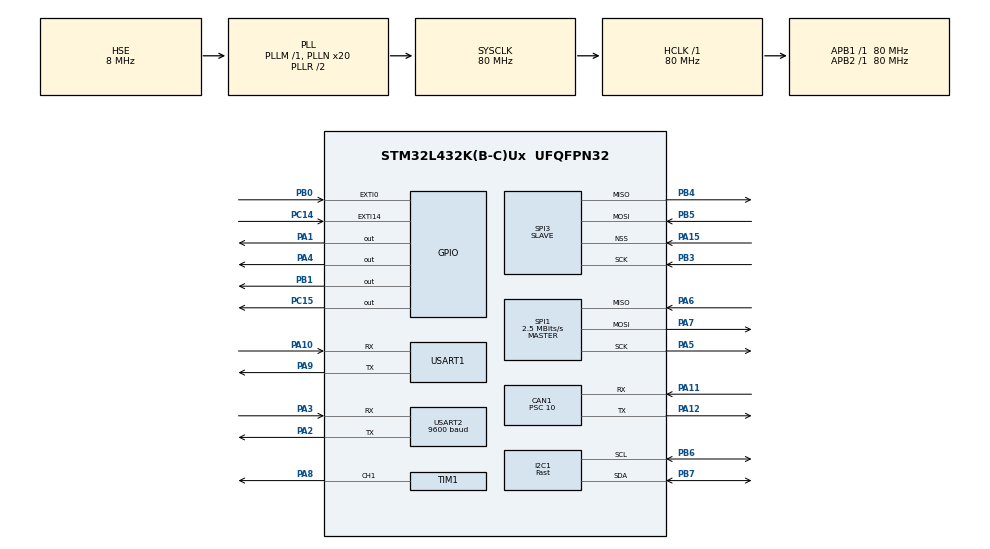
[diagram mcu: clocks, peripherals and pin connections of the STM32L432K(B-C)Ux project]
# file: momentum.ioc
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ADC1.Channel-0\#ChannelRegularConversion=ADC_CHANNEL_VREFINT
ADC1.Channel-1\#ChannelRegularConversion=ADC_CHANNEL_TEMPSENSOR
ADC1.NbrOfConversion=2
ADC1.NbrOfConversionFlag=1
ADC1.OffsetNumber-0\#ChannelRegularConversion=ADC_OFFSET_NONE
ADC1.OffsetNumber-1\#ChannelRegularConversion=ADC_OFFSET_NONE
ADC1.Overrun=ADC_OVR_DATA_OVERWRITTEN
ADC1.OversamplingMode=DISABLE
ADC1.Rank-0\#ChannelRegularConversion=1
ADC1.Rank-1\#ChannelRegularConversion=2
ADC1.SamplingTime-0\#ChannelRegularConversion=ADC_SAMPLETIME_640CYCLES_5
ADC1.SamplingTime-1\#ChannelRegularConversion=ADC_SAMPLETIME_640CYCLES_5
ADC1.master=1
CAN1.ABOM=ENABLE
CAN1.BS1=CAN_BS1_13TQ
CAN1.BS2=CAN_BS2_2TQ
CAN1.CalculateBaudRate=500000
CAN1.CalculateTimeBit=2000
CAN1.CalculateTimeQuantum=125.0
CAN1.NART=ENABLE
CAN1.Prescaler=10
Dma.ADC1.9.Direction=DMA_PERIPH_TO_MEMORY
Dma.ADC1.9.Instance=DMA1_Channel1
Dma.ADC1.9.MemDataAlignment=DMA_MDATAALIGN_WORD
Dma.ADC1.9.MemInc=DMA_MINC_ENABLE
Dma.ADC1.9.Mode=DMA_NORMAL
Dma.ADC1.9.PeriphDataAlignment=DMA_PDATAALIGN_WORD
Dma.ADC1.9.PeriphInc=DMA_PINC_DISABLE
Dma.ADC1.9.Priority=DMA_PRIORITY_LOW
Dma.Request0=SPI1_RX
Dma.Request1=SPI1_TX
Dma.Request2=USART2_RX
Dma.Request3=USART2_TX
Dma.Request4=SPI3_TX
Dma.Request5=SPI3_RX
Dma.Request6=TIM1_CH1
Dma.Request7=USART1_RX
Dma.Request8=USART1_TX
Dma.Request9=ADC1
Dma.SPI1_RX.0.Direction=DMA_PERIPH_TO_MEMORY
Dma.SPI1_RX.0.Instance=DMA2_Channel3
Dma.SPI1_RX.0.MemDataAlignment=DMA_MDATAALIGN_BYTE
Dma.SPI1_RX.0.MemInc=DMA_MINC_ENABLE
Dma.SPI1_RX.0.Mode=DMA_NORMAL
Dma.SPI1_RX.0.PeriphDataAlignment=DMA_PDATAALIGN_BYTE
Dma.SPI1_RX.0.PeriphInc=DMA_PINC_DISABLE
Dma.SPI1_RX.0.Priority=DMA_PRIORITY_LOW
Dma.SPI1_TX.1.Direction=DMA_MEMORY_TO_PERIPH
Dma.SPI1_TX.1.Instance=DMA1_Channel3
Dma.SPI1_TX.1.MemDataAlignment=DMA_MDATAALIGN_BYTE
Dma.SPI1_TX.1.MemInc=DMA_MINC_ENABLE
Dma.SPI1_TX.1.Mode=DMA_NORMAL
Dma.SPI1_TX.1.PeriphDataAlignment=DMA_PDATAALIGN_BYTE
Dma.SPI1_TX.1.PeriphInc=DMA_PINC_DISABLE
Dma.SPI1_TX.1.Priority=DMA_PRIORITY_LOW
Dma.SPI3_RX.5.Direction=DMA_PERIPH_TO_MEMORY
Dma.SPI3_RX.5.Instance=DMA2_Channel1
Dma.SPI3_RX.5.MemDataAlignment=DMA_MDATAALIGN_BYTE
Dma.SPI3_RX.5.MemInc=DMA_MINC_ENABLE
Dma.SPI3_RX.5.Mode=DMA_NORMAL
Dma.SPI3_RX.5.PeriphDataAlignment=DMA_PDATAALIGN_BYTE
Dma.SPI3_RX.5.PeriphInc=DMA_PINC_DISABLE
Dma.SPI3_RX.5.Priority=DMA_PRIORITY_LOW
Dma.SPI3_TX.4.Direction=DMA_MEMORY_TO_PERIPH
Dma.SPI3_TX.4.Instance=DMA2_Channel2
Dma.SPI3_TX.4.MemDataAlignment=DMA_MDATAALIGN_BYTE
Dma.SPI3_TX.4.MemInc=DMA_MINC_ENABLE
Dma.SPI3_TX.4.Mode=DMA_NORMAL
Dma.SPI3_TX.4.PeriphDataAlignment=DMA_PDATAALIGN_BYTE
Dma.SPI3_TX.4.PeriphInc=DMA_PINC_DISABLE
Dma.SPI3_TX.4.Priority=DMA_PRIORITY_LOW
Dma.TIM1_CH1.6.Direction=DMA_MEMORY_TO_PERIPH
Dma.TIM1_CH1.6.Instance=DMA1_Channel2
Dma.TIM1_CH1.6.MemDataAlignment=DMA_MDATAALIGN_HALFWORD
Dma.TIM1_CH1.6.MemInc=DMA_MINC_ENABLE
Dma.TIM1_CH1.6.Mode=DMA_NORMAL
Dma.TIM1_CH1.6.PeriphDataAlignment=DMA_PDATAALIGN_HALFWORD
Dma.TIM1_CH1.6.PeriphInc=DMA_PINC_DISABLE
Dma.TIM1_CH1.6.Priority=DMA_PRIORITY_LOW
Dma.USART1_RX.7.Direction=DMA_PERIPH_TO_MEMORY
Dma.USART1_RX.7.Instance=DMA1_Channel5
Dma.USART1_RX.7.MemDataAlignment=DMA_MDATAALIGN_BYTE
Dma.USART1_RX.7.MemInc=DMA_MINC_ENABLE
Dma.USART1_RX.7.Mode=DMA_NORMAL
Dma.USART1_RX.7.PeriphDataAlignment=DMA_PDATAALIGN_BYTE
Dma.USART1_RX.7.PeriphInc=DMA_PINC_DISABLE
Dma.USART1_RX.7.Priority=DMA_PRIORITY_LOW
Dma.USART1_TX.8.Direction=DMA_MEMORY_TO_PERIPH
Dma.USART1_TX.8.Instance=DMA1_Channel4
Dma.USART1_TX.8.MemDataAlignment=DMA_MDATAALIGN_BYTE
Dma.USART1_TX.8.MemInc=DMA_MINC_ENABLE
Dma.USART1_TX.8.Mode=DMA_NORMAL
Dma.USART1_TX.8.PeriphDataAlignment=DMA_PDATAALIGN_BYTE
Dma.USART1_TX.8.PeriphInc=DMA_PINC_DISABLE
Dma.USART1_TX.8.Priority=DMA_PRIORITY_LOW
Dma.USART2_RX.2.Direction=DMA_PERIPH_TO_MEMORY
Dma.USART2_RX.2.Instance=DMA1_Channel6
Dma.USART2_RX.2.MemDataAlignment=DMA_MDATAALIGN_BYTE
Dma.USART2_RX.2.MemInc=DMA_MINC_ENABLE
Dma.USART2_RX.2.Mode=DMA_CIRCULAR
Dma.USART2_RX.2.PeriphDataAlignment=DMA_PDATAALIGN_BYTE
Dma.USART2_RX.2.PeriphInc=DMA_PINC_DISABLE
Dma.USART2_RX.2.Priority=DMA_PRIORITY_LOW
Dma.USART2_TX.3.Direction=DMA_MEMORY_TO_PERIPH
Dma.USART2_TX.3.Instance=DMA1_Channel7
Dma.USART2_TX.3.MemDataAlignment=DMA_MDATAALIGN_BYTE
Dma.USART2_TX.3.MemInc=DMA_MINC_ENABLE
Dma.USART2_TX.3.Mode=DMA_NORMAL
Dma.USART2_TX.3.PeriphDataAlignment=DMA_PDATAALIGN_BYTE
Dma.USART2_TX.3.PeriphInc=DMA_PINC_DISABLE
Dma.USART2_TX.3.Priority=DMA_PRIORITY_LOW
I2C1.I2C_Speed_Mode=I2C_Fast
I2C1.Timing=0x00F12981
Mcu.Family=STM32L4
Mcu.Name=STM32L432K(B-C)Ux
Mcu.Package=UFQFPN32
NVIC.CAN1_RX0_IRQn=true\:1\:0\:true\:false\:true\:true\:true\:true
NVIC.CAN1_RX1_IRQn=true\:1\:0\:true\:false\:true\:true\:true\:true
NVIC.DMA1_Channel1_IRQn=true\:3\:0\:true\:false\:true\:false\:true\:true
NVIC.DMA1_Channel2_IRQn=true\:3\:0\:true\:false\:true\:false\:true\:true
NVIC.DMA1_Channel3_IRQn=true\:1\:0\:true\:false\:true\:false\:true\:true
NVIC.DMA1_Channel4_IRQn=true\:0\:0\:false\:false\:true\:false\:true\:true
NVIC.DMA1_Channel5_IRQn=true\:0\:0\:false\:false\:true\:false\:true\:true
NVIC.DMA1_Channel6_IRQn=true\:2\:0\:true\:false\:true\:false\:true\:true
NVIC.DMA1_Channel7_IRQn=true\:2\:0\:true\:false\:true\:false\:true\:true
NVIC.DMA2_Channel1_IRQn=true\:0\:0\:false\:false\:true\:false\:true\:true
NVIC.DMA2_Channel2_IRQn=true\:0\:0\:false\:false\:true\:false\:true\:true
NVIC.DMA2_Channel3_IRQn=true\:1\:0\:true\:false\:true\:false\:true\:true
NVIC.EXTI0_IRQn=true\:2\:0\:true\:false\:true\:true\:true\:true
NVIC.EXTI15_10_IRQn=true\:0\:0\:false\:false\:true\:true\:true\:true
NVIC.PriorityGroup=NVIC_PRIORITYGROUP_4
NVIC.SPI3_IRQn=true\:0\:0\:false\:false\:true\:true\:true\:true
NVIC.USART2_IRQn=true\:2\:0\:true\:false\:true\:true\:true\:true
PA0.Mode=HSE-External-Clock-Source-for-LittleOrca
PA0.Signal=RCC_CK_IN
PA1.GPIO_PuPd=GPIO_NOPULL
PA1.PinState=GPIO_PIN_SET
PA1.Signal=GPIO_Output
PA10.Mode=Asynchronous
PA10.Signal=USART1_RX
PA11.Mode=CAN_Activate
PA11.Signal=CAN1_RX
PA12.Mode=CAN_Activate
PA12.Signal=CAN1_TX
PA13\ (JTMS-SWDIO).Mode=Serial_Wire
PA13\ (JTMS-SWDIO).Signal=SYS_JTMS-SWDIO
PA14\ (JTCK-SWCLK).Mode=Serial_Wire
PA14\ (JTCK-SWCLK).Signal=SYS_JTCK-SWCLK
PA15\ (JTDI).Mode=NSS_Signal_Hard_Input
PA15\ (JTDI).Signal=SPI3_NSS
PA2.Mode=Asynchronous
PA2.Signal=USART2_TX
PA3.Mode=Asynchronous
PA3.Signal=USART2_RX
PA4.GPIO_PuPd=GPIO_NOPULL
PA4.PinState=GPIO_PIN_SET
PA4.Signal=GPIO_Output
PA5.Mode=Full_Duplex_Master
PA5.Signal=SPI1_SCK
PA6.Mode=Full_Duplex_Master
PA6.Signal=SPI1_MISO
PA7.Mode=Full_Duplex_Master
PA7.Signal=SPI1_MOSI
PA8.Signal=S_TIM1_CH1
PA9.Mode=Asynchronous
PA9.Signal=USART1_TX
PB0.GPIO_ModeDefaultEXTI=GPIO_MODE_IT_FALLING
PB0.GPIO_PuPd=GPIO_PULLUP
PB0.Signal=GPXTI0
PB1.PinState=GPIO_PIN_SET
PB1.Signal=GPIO_Output
PB3\ (JTDO-TRACESWO).Mode=Full_Duplex_Slave
PB3\ (JTDO-TRACESWO).Signal=SPI3_SCK
PB4\ (NJTRST).Mode=Full_Duplex_Slave
PB4\ (NJTRST).Signal=SPI3_MISO
PB5.Mode=Full_Duplex_Slave
PB5.Signal=SPI3_MOSI
PB6.Mode=I2C
PB6.Signal=I2C1_SCL
PB7.Mode=I2C
PB7.Signal=I2C1_SDA
PC14-OSC32_IN\ (PC14).Signal=GPXTI14
PC15-OSC32_OUT\ (PC15).PinState=GPIO_PIN_SET
PC15-OSC32_OUT\ (PC15).Signal=GPIO_Output
ProjectManager.HeapSize=0x200
ProjectManager.StackSize=0x400
ProjectManager.TargetToolchain=CMake
RCC.ADCFreq_Value=32000000
RCC.AHBFreq_Value=80000000
RCC.APB1Freq_Value=80000000
RCC.APB1TimFreq_Value=80000000
RCC.APB2Freq_Value=80000000
RCC.APB2TimFreq_Value=80000000
RCC.CortexFreq_Value=80000000
RCC.HCLKFreq_Value=80000000
RCC.HSE_VALUE=8000000
RCC.HSI48_VALUE=48000000
RCC.HSI_VALUE=16000000
RCC.LSE_VALUE=32768
RCC.MSI_VALUE=4000000
RCC.PLLN=20
RCC.PLLSourceVirtual=RCC_PLLSOURCE_HSE
RCC.SYSCLKFreq_VALUE=80000000
RCC.SYSCLKSource=RCC_SYSCLKSOURCE_PLLCLK
RCC.USBFreq_Value=32000000
RCC.VCOOutputFreq_Value=160000000
SH.S_TIM1_CH1.0=TIM1_CH1,PWM Generation1 CH1
SPI1.BaudRatePrescaler=SPI_BAUDRATEPRESCALER_32
SPI1.CLKPhase=SPI_PHASE_2EDGE
SPI1.CLKPolarity=SPI_POLARITY_HIGH
SPI1.CalculateBaudRate=2.5 MBits/s
SPI1.DataSize=SPI_DATASIZE_8BIT
SPI1.Direction=SPI_DIRECTION_2LINES
SPI1.Mode=SPI_MODE_MASTER
SPI1.VirtualType=VM_MASTER
SPI3.DataSize=SPI_DATASIZE_8BIT
SPI3.Direction=SPI_DIRECTION_2LINES
SPI3.Mode=SPI_MODE_SLAVE
SPI3.VirtualNSS=VM_NSSHARD
SPI3.VirtualType=VM_SLAVE
TIM1.Channel-PWM\ Generation1\ CH1=TIM_CHANNEL_1
TIM1.Period=25-1
TIM1.Prescaler=3-1
TIM2.Channel-PWM\ Generation1\ No\ Output=TIM_CHANNEL_1
TIM2.Channel-PWM\ Generation2\ No\ Output=TIM_CHANNEL_2
TIM2.Prescaler=79
USART1.VirtualMode-Asynchronous=VM_ASYNC
USART2.BaudRate=9600
USART2.VirtualMode-Asynchronous=VM_ASYNC
VP_ADC1_TempSens_Input.Mode=IN-TempSens
VP_ADC1_Vref_Input.Mode=IN-Vrefint
VP_RNG_VS_RNG.Mode=RNG_Activate
VP_RTC_VS_RTC_Activate.Mode=RTC_Enabled
VP_RTC_VS_RTC_Calendar.Mode=RTC_Calendar
VP_TIM2_VS_no_output1.Mode=PWM Generation1 No Output
VP_TIM2_VS_no_output2.Mode=PWM Generation2 No Output
board=custom

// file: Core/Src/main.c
/* USER CODE BEGIN Header */
/**
  ******************************************************************************
  * @file           : main.c
  * @brief          : Main program body
  ******************************************************************************
  * @attention
  *
  * Copyright (c) 2025 STMicroelectronics.
  * All rights reserved.
  *
  * This software is licensed under terms that can be found in the LICENSE file
  * in the root directory of this software component.
  * If no LICENSE file comes with this software, it is provided AS-IS.
  *
  ******************************************************************************
  */
/* USER CODE END Header */
#include "main.h"

/* USER CODE BEGIN Includes */
#include "configuration.h"
#include "init.h"
#include "run.h"
/* USER CODE END Includes */

ADC_HandleTypeDef hadc1;
DMA_HandleTypeDef hdma_adc1;

CAN_HandleTypeDef hcan1;

I2C_HandleTypeDef hi2c1;

RNG_HandleTypeDef hrng;

RTC_HandleTypeDef hrtc;

SPI_HandleTypeDef hspi1;
SPI_HandleTypeDef hspi3;
DMA_HandleTypeDef hdma_spi1_rx;
DMA_HandleTypeDef hdma_spi1_tx;
DMA_HandleTypeDef hdma_spi3_tx;
DMA_HandleTypeDef hdma_spi3_rx;

TIM_HandleTypeDef htim1;
TIM_HandleTypeDef htim2;
DMA_HandleTypeDef hdma_tim1_ch1;

UART_HandleTypeDef huart1;
UART_HandleTypeDef huart2;
DMA_HandleTypeDef hdma_usart1_rx;
DMA_HandleTypeDef hdma_usart1_tx;
DMA_HandleTypeDef hdma_usart2_rx;
DMA_HandleTypeDef hdma_usart2_tx;

void SystemClock_Config(void);
void PeriphCommonClock_Config(void);
static void MX_GPIO_Init(void);
static void MX_DMA_Init(void);
static void MX_I2C1_Init(void);
static void MX_SPI1_Init(void);
static void MX_TIM1_Init(void);
static void MX_TIM2_Init(void);
static void MX_USART1_UART_Init(void);
static void MX_USART2_UART_Init(void);
static void MX_SPI3_Init(void);
static void MX_CAN1_Init(void);
static void MX_RNG_Init(void);
static void MX_RTC_Init(void);
static void MX_ADC1_Init(void);

int main(void)
{

  /* MCU Configuration--------------------------------------------------------*/

  /* Reset of all peripherals, Initializes the Flash interface and the Systick. */
  HAL_Init();

  /* Configure the system clock */
  SystemClock_Config();

  /* Configure the peripherals common clocks */
  PeriphCommonClock_Config();

  /* Initialize all configured peripherals */
  MX_GPIO_Init();
  MX_DMA_Init();
  MX_I2C1_Init();
  MX_SPI1_Init();
  MX_TIM1_Init();
  MX_TIM2_Init();
  MX_USART1_UART_Init();
  MX_USART2_UART_Init();
  MX_SPI3_Init();
  MX_CAN1_Init();
  MX_RNG_Init();
  MX_RTC_Init();
  MX_ADC1_Init();

  /* Infinite loop */
  /* USER CODE BEGIN WHILE */
  momentum_init();

  while (1) {
    momentum_run();
    /* USER CODE END WHILE */

  }
}

void SystemClock_Config(void)
{
  RCC_OscInitTypeDef RCC_OscInitStruct = {0};
  RCC_ClkInitTypeDef RCC_ClkInitStruct = {0};

  /** Configure the main internal regulator output voltage
  */
  if (HAL_PWREx_ControlVoltageScaling(PWR_REGULATOR_VOLTAGE_SCALE1) != HAL_OK)
  {
    Error_Handler();
  }

  /** Initializes the RCC Oscillators according to the specified parameters
  * in the RCC_OscInitTypeDef structure.
  */
  RCC_OscInitStruct.OscillatorType = RCC_OSCILLATORTYPE_LSI|RCC_OSCILLATORTYPE_HSE;
  RCC_OscInitStruct.HSEState = RCC_HSE_BYPASS;
  RCC_OscInitStruct.LSIState = RCC_LSI_ON;
  RCC_OscInitStruct.PLL.PLLState = RCC_PLL_ON;
  RCC_OscInitStruct.PLL.PLLSource = RCC_PLLSOURCE_HSE;
  RCC_OscInitStruct.PLL.PLLM = 1;
  RCC_OscInitStruct.PLL.PLLN = 20;
  RCC_OscInitStruct.PLL.PLLP = RCC_PLLP_DIV7;
  RCC_OscInitStruct.PLL.PLLQ = RCC_PLLQ_DIV2;
  RCC_OscInitStruct.PLL.PLLR = RCC_PLLR_DIV2;
  if (HAL_RCC_OscConfig(&RCC_OscInitStruct) != HAL_OK)
  {
    Error_Handler();
  }

  /** Initializes the CPU, AHB and APB buses clocks
  */
  RCC_ClkInitStruct.ClockType = RCC_CLOCKTYPE_HCLK|RCC_CLOCKTYPE_SYSCLK
                              |RCC_CLOCKTYPE_PCLK1|RCC_CLOCKTYPE_PCLK2;
  RCC_ClkInitStruct.SYSCLKSource = RCC_SYSCLKSOURCE_PLLCLK;
  RCC_ClkInitStruct.AHBCLKDivider = RCC_SYSCLK_DIV1;
  RCC_ClkInitStruct.APB1CLKDivider = RCC_HCLK_DIV1;
  RCC_ClkInitStruct.APB2CLKDivider = RCC_HCLK_DIV1;

  if (HAL_RCC_ClockConfig(&RCC_ClkInitStruct, FLASH_LATENCY_4) != HAL_OK)
  {
    Error_Handler();
  }
}

void PeriphCommonClock_Config(void)
{
  RCC_PeriphCLKInitTypeDef PeriphClkInit = {0};

  /** Initializes the peripherals clock
  */
  PeriphClkInit.PeriphClockSelection = RCC_PERIPHCLK_RNG|RCC_PERIPHCLK_ADC;
  PeriphClkInit.AdcClockSelection = RCC_ADCCLKSOURCE_PLLSAI1;
  PeriphClkInit.RngClockSelection = RCC_RNGCLKSOURCE_PLLSAI1;
  PeriphClkInit.PLLSAI1.PLLSAI1Source = RCC_PLLSOURCE_HSE;
  PeriphClkInit.PLLSAI1.PLLSAI1M = 1;
  PeriphClkInit.PLLSAI1.PLLSAI1N = 8;
  PeriphClkInit.PLLSAI1.PLLSAI1P = RCC_PLLP_DIV7;
  PeriphClkInit.PLLSAI1.PLLSAI1Q = RCC_PLLQ_DIV2;
  PeriphClkInit.PLLSAI1.PLLSAI1R = RCC_PLLR_DIV2;
  PeriphClkInit.PLLSAI1.PLLSAI1ClockOut = RCC_PLLSAI1_48M2CLK|RCC_PLLSAI1_ADC1CLK;
  if (HAL_RCCEx_PeriphCLKConfig(&PeriphClkInit) != HAL_OK)
  {
    Error_Handler();
  }
}

static void MX_ADC1_Init(void)
{

  ADC_ChannelConfTypeDef sConfig = {0};

  /** Common config
  */
  hadc1.Instance = ADC1;
  hadc1.Init.ClockPrescaler = ADC_CLOCK_ASYNC_DIV1;
  hadc1.Init.Resolution = ADC_RESOLUTION_12B;
  hadc1.Init.DataAlign = ADC_DATAALIGN_RIGHT;
  hadc1.Init.ScanConvMode = ADC_SCAN_ENABLE;
  hadc1.Init.EOCSelection = ADC_EOC_SINGLE_CONV;
  hadc1.Init.LowPowerAutoWait = DISABLE;
  hadc1.Init.ContinuousConvMode = DISABLE;
  hadc1.Init.NbrOfConversion = 2;
  hadc1.Init.DiscontinuousConvMode = DISABLE;
  hadc1.Init.ExternalTrigConv = ADC_SOFTWARE_START;
  hadc1.Init.ExternalTrigConvEdge = ADC_EXTERNALTRIGCONVEDGE_NONE;
  hadc1.Init.DMAContinuousRequests = DISABLE;
  hadc1.Init.Overrun = ADC_OVR_DATA_OVERWRITTEN;
  hadc1.Init.OversamplingMode = DISABLE;
  if (HAL_ADC_Init(&hadc1) != HAL_OK)
  {
    Error_Handler();
  }

  /** Configure Regular Channel
  */
  sConfig.Channel = ADC_CHANNEL_VREFINT;
  sConfig.Rank = ADC_REGULAR_RANK_1;
  sConfig.SamplingTime = ADC_SAMPLETIME_640CYCLES_5;
  sConfig.SingleDiff = ADC_SINGLE_ENDED;
  sConfig.OffsetNumber = ADC_OFFSET_NONE;
  sConfig.Offset = 0;
  if (HAL_ADC_ConfigChannel(&hadc1, &sConfig) != HAL_OK)
  {
    Error_Handler();
  }

  /** Configure Regular Channel
  */
  sConfig.Channel = ADC_CHANNEL_TEMPSENSOR;
  sConfig.Rank = ADC_REGULAR_RANK_2;
  if (HAL_ADC_ConfigChannel(&hadc1, &sConfig) != HAL_OK)
  {
    Error_Handler();
  }

}

static void MX_CAN1_Init(void)
{

  hcan1.Instance = CAN1;
  hcan1.Init.Prescaler = 10;
  hcan1.Init.Mode = CAN_MODE_NORMAL;
  hcan1.Init.SyncJumpWidth = CAN_SJW_1TQ;
  hcan1.Init.TimeSeg1 = CAN_BS1_13TQ;
  hcan1.Init.TimeSeg2 = CAN_BS2_2TQ;
  hcan1.Init.TimeTriggeredMode = DISABLE;
  hcan1.Init.AutoBusOff = ENABLE;
  hcan1.Init.AutoWakeUp = DISABLE;
  hcan1.Init.AutoRetransmission = ENABLE;
  hcan1.Init.ReceiveFifoLocked = DISABLE;
  hcan1.Init.TransmitFifoPriority = DISABLE;
  if (HAL_CAN_Init(&hcan1) != HAL_OK)
  {
    Error_Handler();
  }

}

static void MX_I2C1_Init(void)
{

  hi2c1.Instance = I2C1;
  hi2c1.Init.Timing = 0x00F12981;
  hi2c1.Init.OwnAddress1 = 0;
  hi2c1.Init.AddressingMode = I2C_ADDRESSINGMODE_7BIT;
  hi2c1.Init.DualAddressMode = I2C_DUALADDRESS_DISABLE;
  hi2c1.Init.OwnAddress2 = 0;
  hi2c1.Init.OwnAddress2Masks = I2C_OA2_NOMASK;
  hi2c1.Init.GeneralCallMode = I2C_GENERALCALL_DISABLE;
  hi2c1.Init.NoStretchMode = I2C_NOSTRETCH_DISABLE;
  if (HAL_I2C_Init(&hi2c1) != HAL_OK)
  {
    Error_Handler();
  }

  /** Configure Analogue filter
  */
  if (HAL_I2CEx_ConfigAnalogFilter(&hi2c1, I2C_ANALOGFILTER_ENABLE) != HAL_OK)
  {
    Error_Handler();
  }

  /** Configure Digital filter
  */
  if (HAL_I2CEx_ConfigDigitalFilter(&hi2c1, 0) != HAL_OK)
  {
    Error_Handler();
  }

}

static void MX_RNG_Init(void)
{

  hrng.Instance = RNG;
  if (HAL_RNG_Init(&hrng) != HAL_OK)
  {
    Error_Handler();
  }

}

static void MX_RTC_Init(void)
{

  RTC_TimeTypeDef sTime = {0};
  RTC_DateTypeDef sDate = {0};

  /** Initialize RTC Only
  */
  hrtc.Instance = RTC;
  hrtc.Init.HourFormat = RTC_HOURFORMAT_24;
  hrtc.Init.AsynchPrediv = 127;
  hrtc.Init.SynchPrediv = 255;
  hrtc.Init.OutPut = RTC_OUTPUT_DISABLE;
  hrtc.Init.OutPutRemap = RTC_OUTPUT_REMAP_NONE;
  hrtc.Init.OutPutPolarity = RTC_OUTPUT_POLARITY_HIGH;
  hrtc.Init.OutPutType = RTC_OUTPUT_TYPE_OPENDRAIN;
  if (HAL_RTC_Init(&hrtc) != HAL_OK)
  {
    Error_Handler();
  }

  /** Initialize RTC and set the Time and Date
  */
  sTime.Hours = 0x0;
  sTime.Minutes = 0x0;
  sTime.Seconds = 0x0;
  sTime.DayLightSaving = RTC_DAYLIGHTSAVING_NONE;
  sTime.StoreOperation = RTC_STOREOPERATION_RESET;
  if (HAL_RTC_SetTime(&hrtc, &sTime, RTC_FORMAT_BCD) != HAL_OK)
  {
    Error_Handler();
  }
  sDate.WeekDay = RTC_WEEKDAY_MONDAY;
  sDate.Month = RTC_MONTH_JANUARY;
  sDate.Date = 0x1;
  sDate.Year = 0x0;

  if (HAL_RTC_SetDate(&hrtc, &sDate, RTC_FORMAT_BCD) != HAL_OK)
  {
    Error_Handler();
  }

}

static void MX_SPI1_Init(void)
{

  /* SPI1 parameter configuration*/
  hspi1.Instance = SPI1;
  hspi1.Init.Mode = SPI_MODE_MASTER;
  hspi1.Init.Direction = SPI_DIRECTION_2LINES;
  hspi1.Init.DataSize = SPI_DATASIZE_8BIT;
  hspi1.Init.CLKPolarity = SPI_POLARITY_HIGH;
  hspi1.Init.CLKPhase = SPI_PHASE_2EDGE;
  hspi1.Init.NSS = SPI_NSS_SOFT;
  hspi1.Init.BaudRatePrescaler = SPI_BAUDRATEPRESCALER_32;
  hspi1.Init.FirstBit = SPI_FIRSTBIT_MSB;
  hspi1.Init.TIMode = SPI_TIMODE_DISABLE;
  hspi1.Init.CRCCalculation = SPI_CRCCALCULATION_DISABLE;
  hspi1.Init.CRCPolynomial = 7;
  hspi1.Init.CRCLength = SPI_CRC_LENGTH_DATASIZE;
  hspi1.Init.NSSPMode = SPI_NSS_PULSE_DISABLE;
  if (HAL_SPI_Init(&hspi1) != HAL_OK)
  {
    Error_Handler();
  }

}

static void MX_SPI3_Init(void)
{

  /* SPI3 parameter configuration*/
  hspi3.Instance = SPI3;
  hspi3.Init.Mode = SPI_MODE_SLAVE;
  hspi3.Init.Direction = SPI_DIRECTION_2LINES;
  hspi3.Init.DataSize = SPI_DATASIZE_8BIT;
  hspi3.Init.CLKPolarity = SPI_POLARITY_LOW;
  hspi3.Init.CLKPhase = SPI_PHASE_1EDGE;
  hspi3.Init.NSS = SPI_NSS_HARD_INPUT;
  hspi3.Init.FirstBit = SPI_FIRSTBIT_MSB;
  hspi3.Init.TIMode = SPI_TIMODE_DISABLE;
  hspi3.Init.CRCCalculation = SPI_CRCCALCULATION_DISABLE;
  hspi3.Init.CRCPolynomial = 7;
  hspi3.Init.CRCLength = SPI_CRC_LENGTH_DATASIZE;
  hspi3.Init.NSSPMode = SPI_NSS_PULSE_DISABLE;
  if (HAL_SPI_Init(&hspi3) != HAL_OK)
  {
    Error_Handler();
  }

}

static void MX_TIM1_Init(void)
{

  TIM_MasterConfigTypeDef sMasterConfig = {0};
  TIM_OC_InitTypeDef sConfigOC = {0};
  TIM_BreakDeadTimeConfigTypeDef sBreakDeadTimeConfig = {0};

  htim1.Instance = TIM1;
  htim1.Init.Prescaler = 3-1;
  htim1.Init.CounterMode = TIM_COUNTERMODE_UP;
  htim1.Init.Period = 25-1;
  htim1.Init.ClockDivision = TIM_CLOCKDIVISION_DIV1;
  htim1.Init.RepetitionCounter = 0;
  htim1.Init.AutoReloadPreload = TIM_AUTORELOAD_PRELOAD_DISABLE;
  if (HAL_TIM_PWM_Init(&htim1) != HAL_OK)
  {
    Error_Handler();
  }
  sMasterConfig.MasterOutputTrigger = TIM_TRGO_RESET;
  sMasterConfig.MasterOutputTrigger2 = TIM_TRGO2_RESET;
  sMasterConfig.MasterSlaveMode = TIM_MASTERSLAVEMODE_DISABLE;
  if (HAL_TIMEx_MasterConfigSynchronization(&htim1, &sMasterConfig) != HAL_OK)
  {
    Error_Handler();
  }
  sConfigOC.OCMode = TIM_OCMODE_PWM1;
  sConfigOC.Pulse = 0;
  sConfigOC.OCPolarity = TIM_OCPOLARITY_HIGH;
  sConfigOC.OCNPolarity = TIM_OCNPOLARITY_HIGH;
  sConfigOC.OCFastMode = TIM_OCFAST_DISABLE;
  sConfigOC.OCIdleState = TIM_OCIDLESTATE_RESET;
  sConfigOC.OCNIdleState = TIM_OCNIDLESTATE_RESET;
  if (HAL_TIM_PWM_ConfigChannel(&htim1, &sConfigOC, TIM_CHANNEL_1) != HAL_OK)
  {
    Error_Handler();
  }
  sBreakDeadTimeConfig.OffStateRunMode = TIM_OSSR_DISABLE;
  sBreakDeadTimeConfig.OffStateIDLEMode = TIM_OSSI_DISABLE;
  sBreakDeadTimeConfig.LockLevel = TIM_LOCKLEVEL_OFF;
  sBreakDeadTimeConfig.DeadTime = 0;
  sBreakDeadTimeConfig.BreakState = TIM_BREAK_DISABLE;
  sBreakDeadTimeConfig.BreakPolarity = TIM_BREAKPOLARITY_HIGH;
  sBreakDeadTimeConfig.BreakFilter = 0;
  sBreakDeadTimeConfig.Break2State = TIM_BREAK2_DISABLE;
  sBreakDeadTimeConfig.Break2Polarity = TIM_BREAK2POLARITY_HIGH;
  sBreakDeadTimeConfig.Break2Filter = 0;
  sBreakDeadTimeConfig.AutomaticOutput = TIM_AUTOMATICOUTPUT_DISABLE;
  if (HAL_TIMEx_ConfigBreakDeadTime(&htim1, &sBreakDeadTimeConfig) != HAL_OK)
  {
    Error_Handler();
  }
  HAL_TIM_MspPostInit(&htim1);

}

static void MX_TIM2_Init(void)
{

  TIM_MasterConfigTypeDef sMasterConfig = {0};
  TIM_OC_InitTypeDef sConfigOC = {0};

  htim2.Instance = TIM2;
  htim2.Init.Prescaler = 79;
  htim2.Init.CounterMode = TIM_COUNTERMODE_UP;
  htim2.Init.Period = 4294967295;
  htim2.Init.ClockDivision = TIM_CLOCKDIVISION_DIV1;
  htim2.Init.AutoReloadPreload = TIM_AUTORELOAD_PRELOAD_DISABLE;
  if (HAL_TIM_PWM_Init(&htim2) != HAL_OK)
  {
    Error_Handler();
  }
  sMasterConfig.MasterOutputTrigger = TIM_TRGO_RESET;
  sMasterConfig.MasterSlaveMode = TIM_MASTERSLAVEMODE_DISABLE;
  if (HAL_TIMEx_MasterConfigSynchronization(&htim2, &sMasterConfig) != HAL_OK)
  {
    Error_Handler();
  }
  sConfigOC.OCMode = TIM_OCMODE_PWM1;
  sConfigOC.Pulse = 0;
  sConfigOC.OCPolarity = TIM_OCPOLARITY_HIGH;
  sConfigOC.OCFastMode = TIM_OCFAST_DISABLE;
  if (HAL_TIM_PWM_ConfigChannel(&htim2, &sConfigOC, TIM_CHANNEL_1) != HAL_OK)
  {
    Error_Handler();
  }
  if (HAL_TIM_PWM_ConfigChannel(&htim2, &sConfigOC, TIM_CHANNEL_2) != HAL_OK)
  {
    Error_Handler();
  }

}

static void MX_USART1_UART_Init(void)
{

  huart1.Instance = USART1;
  huart1.Init.BaudRate = 115200;
  huart1.Init.WordLength = UART_WORDLENGTH_8B;
  huart1.Init.StopBits = UART_STOPBITS_1;
  huart1.Init.Parity = UART_PARITY_NONE;
  huart1.Init.Mode = UART_MODE_TX_RX;
  huart1.Init.HwFlowCtl = UART_HWCONTROL_NONE;
  huart1.Init.OverSampling = UART_OVERSAMPLING_16;
  huart1.Init.OneBitSampling = UART_ONE_BIT_SAMPLE_DISABLE;
  huart1.AdvancedInit.AdvFeatureInit = UART_ADVFEATURE_NO_INIT;
  if (HAL_UART_Init(&huart1) != HAL_OK)
  {
    Error_Handler();
  }

}

static void MX_USART2_UART_Init(void)
{

  huart2.Instance = USART2;
  huart2.Init.BaudRate = 9600;
  huart2.Init.WordLength = UART_WORDLENGTH_8B;
  huart2.Init.StopBits = UART_STOPBITS_1;
  huart2.Init.Parity = UART_PARITY_NONE;
  huart2.Init.Mode = UART_MODE_TX_RX;
  huart2.Init.HwFlowCtl = UART_HWCONTROL_NONE;
  huart2.Init.OverSampling = UART_OVERSAMPLING_16;
  huart2.Init.OneBitSampling = UART_ONE_BIT_SAMPLE_DISABLE;
  huart2.AdvancedInit.AdvFeatureInit = UART_ADVFEATURE_NO_INIT;
  if (HAL_UART_Init(&huart2) != HAL_OK)
  {
    Error_Handler();
  }

}

static void MX_DMA_Init(void)
{

  /* DMA controller clock enable */
  __HAL_RCC_DMA2_CLK_ENABLE();
  __HAL_RCC_DMA1_CLK_ENABLE();

  /* DMA interrupt init */
  /* DMA1_Channel1_IRQn interrupt configuration */
  HAL_NVIC_SetPriority(DMA1_Channel1_IRQn, 3, 0);
  HAL_NVIC_EnableIRQ(DMA1_Channel1_IRQn);
  /* DMA1_Channel2_IRQn interrupt configuration */
  HAL_NVIC_SetPriority(DMA1_Channel2_IRQn, 3, 0);
  HAL_NVIC_EnableIRQ(DMA1_Channel2_IRQn);
  /* DMA1_Channel3_IRQn interrupt configuration */
  HAL_NVIC_SetPriority(DMA1_Channel3_IRQn, 1, 0);
  HAL_NVIC_EnableIRQ(DMA1_Channel3_IRQn);
  /* DMA1_Channel4_IRQn interrupt configuration */
  HAL_NVIC_SetPriority(DMA1_Channel4_IRQn, 0, 0);
  HAL_NVIC_EnableIRQ(DMA1_Channel4_IRQn);
  /* DMA1_Channel5_IRQn interrupt configuration */
  HAL_NVIC_SetPriority(DMA1_Channel5_IRQn, 0, 0);
  HAL_NVIC_EnableIRQ(DMA1_Channel5_IRQn);
  /* DMA1_Channel6_IRQn interrupt configuration */
  HAL_NVIC_SetPriority(DMA1_Channel6_IRQn, 2, 0);
  HAL_NVIC_EnableIRQ(DMA1_Channel6_IRQn);
  /* DMA1_Channel7_IRQn interrupt configuration */
  HAL_NVIC_SetPriority(DMA1_Channel7_IRQn, 2, 0);
  HAL_NVIC_EnableIRQ(DMA1_Channel7_IRQn);
  /* DMA2_Channel1_IRQn interrupt configuration */
  HAL_NVIC_SetPriority(DMA2_Channel1_IRQn, 0, 0);
  HAL_NVIC_EnableIRQ(DMA2_Channel1_IRQn);
  /* DMA2_Channel2_IRQn interrupt configuration */
  HAL_NVIC_SetPriority(DMA2_Channel2_IRQn, 0, 0);
  HAL_NVIC_EnableIRQ(DMA2_Channel2_IRQn);
  /* DMA2_Channel3_IRQn interrupt configuration */
  HAL_NVIC_SetPriority(DMA2_Channel3_IRQn, 1, 0);
  HAL_NVIC_EnableIRQ(DMA2_Channel3_IRQn);

}

static void MX_GPIO_Init(void)
{
  GPIO_InitTypeDef GPIO_InitStruct = {0};

  /* GPIO Ports Clock Enable */
  __HAL_RCC_GPIOC_CLK_ENABLE();
  __HAL_RCC_GPIOA_CLK_ENABLE();
  __HAL_RCC_GPIOB_CLK_ENABLE();

  /*Configure GPIO pin Output Level */
  HAL_GPIO_WritePin(GPIOC, GPIO_PIN_15, GPIO_PIN_SET);

  /*Configure GPIO pin Output Level */
  HAL_GPIO_WritePin(GPIOA, GPIO_PIN_1|GPIO_PIN_4, GPIO_PIN_SET);

  /*Configure GPIO pin Output Level */
  HAL_GPIO_WritePin(GPIOB, GPIO_PIN_1, GPIO_PIN_SET);

  /*Configure GPIO pin : PC14 */
  GPIO_InitStruct.Pin = GPIO_PIN_14;
  GPIO_InitStruct.Mode = GPIO_MODE_IT_RISING;
  GPIO_InitStruct.Pull = GPIO_NOPULL;
  HAL_GPIO_Init(GPIOC, &GPIO_InitStruct);

  /*Configure GPIO pin : PC15 */
  GPIO_InitStruct.Pin = GPIO_PIN_15;
  GPIO_InitStruct.Mode = GPIO_MODE_OUTPUT_PP;
  GPIO_InitStruct.Pull = GPIO_NOPULL;
  GPIO_InitStruct.Speed = GPIO_SPEED_FREQ_LOW;
  HAL_GPIO_Init(GPIOC, &GPIO_InitStruct);

  /*Configure GPIO pins : PA1 PA4 */
  GPIO_InitStruct.Pin = GPIO_PIN_1|GPIO_PIN_4;
  GPIO_InitStruct.Mode = GPIO_MODE_OUTPUT_PP;
  GPIO_InitStruct.Pull = GPIO_NOPULL;
  GPIO_InitStruct.Speed = GPIO_SPEED_FREQ_LOW;
  HAL_GPIO_Init(GPIOA, &GPIO_InitStruct);

  /*Configure GPIO pin : PB0 */
  GPIO_InitStruct.Pin = GPIO_PIN_0;
  GPIO_InitStruct.Mode = GPIO_MODE_IT_FALLING;
  GPIO_InitStruct.Pull = GPIO_PULLUP;
  HAL_GPIO_Init(GPIOB, &GPIO_InitStruct);

  /*Configure GPIO pin : PB1 */
  GPIO_InitStruct.Pin = GPIO_PIN_1;
  GPIO_InitStruct.Mode = GPIO_MODE_OUTPUT_PP;
  GPIO_InitStruct.Pull = GPIO_NOPULL;
  GPIO_InitStruct.Speed = GPIO_SPEED_FREQ_LOW;
  HAL_GPIO_Init(GPIOB, &GPIO_InitStruct);

  /* EXTI interrupt init*/
  HAL_NVIC_SetPriority(EXTI0_IRQn, 2, 0);
  HAL_NVIC_EnableIRQ(EXTI0_IRQn);

  HAL_NVIC_SetPriority(EXTI15_10_IRQn, 0, 0);
  HAL_NVIC_EnableIRQ(EXTI15_10_IRQn);

}

void Error_Handler(void)
{
  __disable_irq();
  while (1)
  {
  }
}
